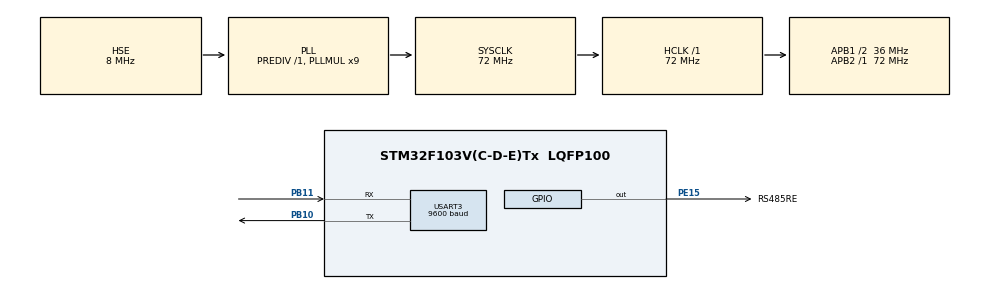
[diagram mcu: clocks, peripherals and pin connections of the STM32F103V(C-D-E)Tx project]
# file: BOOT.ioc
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Mcu.Family=STM32F1
Mcu.Name=STM32F103V(C-D-E)Tx
Mcu.Package=LQFP100
NVIC.PriorityGroup=NVIC_PRIORITYGROUP_4
NVIC.USART3_IRQn=true\:3\:0\:true\:false\:true\:true\:true\:true
OSC_IN.Mode=HSE-External-Oscillator
OSC_IN.Signal=RCC_OSC_IN
OSC_OUT.Mode=HSE-External-Oscillator
OSC_OUT.Signal=RCC_OSC_OUT
PA13.Mode=Serial_Wire
PA13.Signal=SYS_JTMS-SWDIO
PA14.Mode=Serial_Wire
PA14.Signal=SYS_JTCK-SWCLK
PB10.Mode=Asynchronous
PB10.Signal=USART3_TX
PB11.Mode=Asynchronous
PB11.Signal=USART3_RX
PE15.GPIO_Label=RS485RE
PE15.GPIO_Speed=GPIO_SPEED_FREQ_HIGH
PE15.Signal=GPIO_Output
ProjectManager.HeapSize=0x200
ProjectManager.StackSize=0x400
ProjectManager.TargetToolchain=CMake
RCC.AHBFreq_Value=72000000
RCC.APB1CLKDivider=RCC_HCLK_DIV2
RCC.APB1Freq_Value=36000000
RCC.APB1TimFreq_Value=72000000
RCC.APB2Freq_Value=72000000
RCC.APB2TimFreq_Value=72000000
RCC.HCLKFreq_Value=72000000
RCC.PLLMUL=RCC_PLL_MUL9
RCC.PLLSourceVirtual=RCC_PLLSOURCE_HSE
RCC.SYSCLKFreq_VALUE=72000000
RCC.SYSCLKSource=RCC_SYSCLKSOURCE_PLLCLK
RCC.USBFreq_Value=72000000
USART3.BaudRate=9600
USART3.VirtualMode=VM_ASYNC
VP_RTC_VS_RTC_Activate.Mode=RTC_Enabled
VP_RTC_VS_RTC_Calendar.Mode=RTC_Calendar
board=custom

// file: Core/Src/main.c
/* USER CODE BEGIN Header */
/**
 ******************************************************************************
 * @file           : main.c
 * @brief          : Main program body
 ******************************************************************************
 * @attention
 *
 * Copyright (c) 2026 STMicroelectronics.
 * All rights reserved.
 *
 * This software is licensed under terms that can be found in the LICENSE file
 * in the root directory of this software component.
 * If no LICENSE file comes with this software, it is provided AS-IS.
 *
 ******************************************************************************
 */
/* USER CODE END Header */
#include "main.h"
#include "gpio.h"
#include "rtc.h"
#include "usart.h"

/* USER CODE BEGIN Includes */
#include "../Inc/iap/bootloader.h"
#include "../Inc/iap/iap_protocol.h"
#include "../Inc/iap/flash_operations.h"
#include <stdint.h>

/* USER CODE END Includes */

void SystemClock_Config(void);
/* USER CODE BEGIN PFP */
extern void Bootloader_UARTCallback(UART_HandleTypeDef *huart);
extern void Bootloader_CheckAndStartFromRTC(void);
/* USER CODE END PFP */

int main(void)
{

    /* MCU Configuration--------------------------------------------------------*/

    /* Reset of all peripherals, Initializes the Flash interface and the Systick. */
    HAL_Init();

    /* Configure the system clock */
    SystemClock_Config();

    /* Initialize all configured peripherals */
    MX_GPIO_Init();
    MX_USART3_UART_Init();
    MX_RTC_Init();
    /* USER CODE BEGIN 2 */
    // init bootloader
    Bootloader_Init();
    Bootloader_CheckAndStartFromRTC();

    Bootloader_Main();

    //Should never return
    NVIC_SystemReset();
    /* USER CODE END 2 */

    /* Infinite loop */
    /* USER CODE BEGIN WHILE */
    while (1) {
        // Will not reach here
    }
    /* USER CODE END WHILE */

}

void SystemClock_Config(void)
{
    RCC_OscInitTypeDef RCC_OscInitStruct = {0};
    RCC_ClkInitTypeDef RCC_ClkInitStruct = {0};
    RCC_PeriphCLKInitTypeDef PeriphClkInit = {0};

    /** Initializes the RCC Oscillators according to the specified parameters
     * in the RCC_OscInitTypeDef structure.
     */
    RCC_OscInitStruct.OscillatorType = RCC_OSCILLATORTYPE_LSI | RCC_OSCILLATORTYPE_HSE;
    RCC_OscInitStruct.HSEState = RCC_HSE_ON;
    RCC_OscInitStruct.HSEPredivValue = RCC_HSE_PREDIV_DIV1;
    RCC_OscInitStruct.HSIState = RCC_HSI_ON;
    RCC_OscInitStruct.LSIState = RCC_LSI_ON;
    RCC_OscInitStruct.PLL.PLLState = RCC_PLL_ON;
    RCC_OscInitStruct.PLL.PLLSource = RCC_PLLSOURCE_HSE;
    RCC_OscInitStruct.PLL.PLLMUL = RCC_PLL_MUL9;
    if (HAL_RCC_OscConfig(&RCC_OscInitStruct) != HAL_OK) {
        Error_Handler();
    }

    /** Initializes the CPU, AHB and APB buses clocks
     */
    RCC_ClkInitStruct.ClockType = RCC_CLOCKTYPE_HCLK | RCC_CLOCKTYPE_SYSCLK | RCC_CLOCKTYPE_PCLK1 | RCC_CLOCKTYPE_PCLK2;
    RCC_ClkInitStruct.SYSCLKSource = RCC_SYSCLKSOURCE_PLLCLK;
    RCC_ClkInitStruct.AHBCLKDivider = RCC_SYSCLK_DIV1;
    RCC_ClkInitStruct.APB1CLKDivider = RCC_HCLK_DIV2;
    RCC_ClkInitStruct.APB2CLKDivider = RCC_HCLK_DIV1;

    if (HAL_RCC_ClockConfig(&RCC_ClkInitStruct, FLASH_LATENCY_2) != HAL_OK) {
        Error_Handler();
    }
    PeriphClkInit.PeriphClockSelection = RCC_PERIPHCLK_RTC;
    PeriphClkInit.RTCClockSelection = RCC_RTCCLKSOURCE_LSI;
    if (HAL_RCCEx_PeriphCLKConfig(&PeriphClkInit) != HAL_OK) {
        Error_Handler();
    }
}

/* USER CODE BEGIN 4 */

// UART receive complete callback
void HAL_UART_RxCpltCallback(UART_HandleTypeDef *huart)
{
    /* USER CODE BEGIN Callback 0 */
    if (huart->Instance == USART3) {

        // Pass to bootloader handler
        Bootloader_UARTCallback(huart);
    }
    /* USER CODE END Callback 0 */
}

/* USER CODE END 4 */

void Error_Handler(void)
{
    __disable_irq();
    while (1) {
    }
}
#ifdef USE_FULL_ASSERT
/**
 * @brief  Reports the name of the source file and the source line number
 *         where the assert_param error has occurred.
 * @param  file: pointer to the source file name
 * @param  line: assert_param error line source number
 * @retval None
 */
void assert_failed(uint8_t *file, uint32_t line)
{
    /* USER CODE BEGIN 6 */
    /* User can add his own implementation to report the file name and line
       number, ex: printf("Wrong parameters value: file %s on line %d\r\n", file,
       line) */
    /* USER CODE END 6 */
}
#endif /* USE_FULL_ASSERT */
